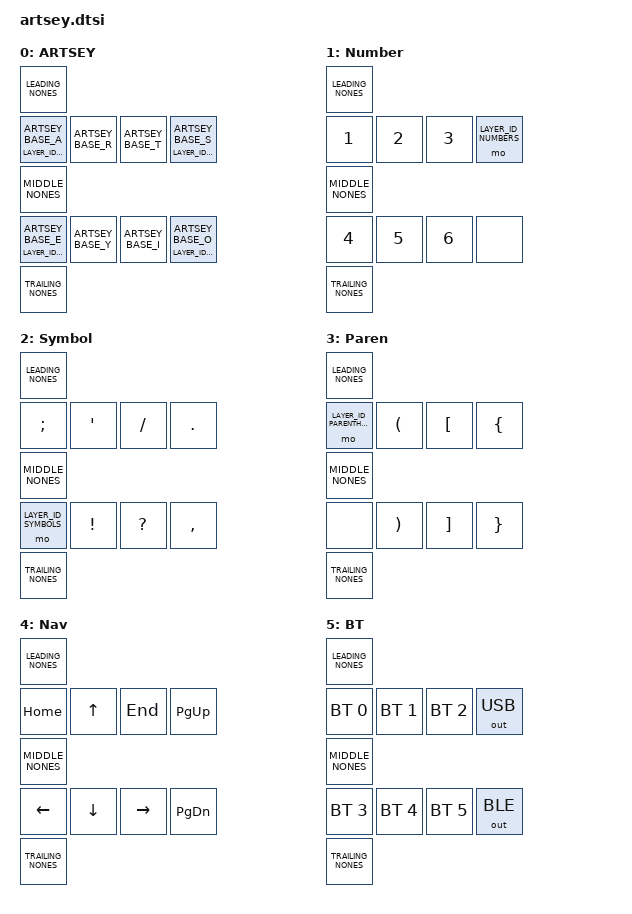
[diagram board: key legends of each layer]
/*
 * Copyright (c) 2021 Mike "KemoNine" Crosson
 *
 * SPDX-License-Identifier: MIT
 */

#include <behaviors.dtsi>
#include <dt-bindings/zmk/keys.h>
#include <dt-bindings/zmk/outputs.h>

#define ZMK_POINTING_DEFAULT_MOVE_VAL 500  // default: 600
#define ZMK_POINTING_DEFAULT_SCRL_VAL 15    // default: 10

#include <dt-bindings/zmk/pointing.h>

&mmv {
    x-input-code = <INPUT_REL_X>;
    y-input-code = <INPUT_REL_Y>;
    time-to-max-speed-ms = <0>;
    acceleration-exponent = <0>;
};

&msc {
    x-input-code = <INPUT_REL_HWHEEL>;
    y-input-code = <INPUT_REL_WHEEL>;
    time-to-max-speed-ms = <0>;
    acceleration-exponent = <0>;
};

/*****************************************
 * Macros for filling in "&none" in the right places in the keymap for re-use needs
 *****************************************/
#define NONE0(X)
#define NONE1(X) X
#define NONE2(X) NONE1(X) X
#define NONE3(X) NONE2(X) X
#define NONE4(X) NONE3(X) X
#define NONE5(X) NONE4(X) X
#define NONE6(X) NONE5(X) X
#define NONE7(X) NONE6(X) X
#define NONE8(X) NONE7(X) X
#define NONE9(X) NONE8(X) X
#define NONE10(X) NONE9(X) X

#define NONE(HUNDREDS,TENS,ONES) \
  NONE##HUNDREDS(NONE10(NONE10(&none))) \
  NONE##TENS(NONE10(&none)) \
  NONE##ONES(&none)

/*****************************************
 * ARTSEY website : https://www.artsey.io
 * Primary reference : https://www.artsey.io/_FILES/images/ARTSEY.jpg
*****************************************/

/*****************************************
 * Setting up ARTSEY comboing
 *   - Enabled right OR left handed orientation
 *   - Please note: A/E key positions should be on your INDEX finger
 *     - The online reference is for right handed use
 *     - When using the ARTSEY layout left handed you'll want to ensure your keypositions are flipped along the Y axis
 *   - Update/adjust the key positions using your boards keymap 
 *     - See below for additional details
 *   - YOU MUST SET THE FOLLOWING CONFIG VALUES FOR THIS SETUP TO WORK PROPERLY IN YOUR BOARDS .conf FILE
 *     - CONFIG_ZMK_COMBO_MAX_COMBOS_PER_KEY=16
 *     - CONFIG_ZMK_COMBO_MAX_KEYS_PER_COMBO=8
 *     - CONFIG_ZMK_COMBO_MAX_PRESSED_COMBOS=8
 *****************************************/

/*****************************************
 * Define which layout you want to use
 *  ONLY ENABLE ONE OF THESE
*****************************************/
#define ARTSEY_RIGHT 1


/*****************************************
 * Define key positions used for combos
 * These definitions are used to define the various ARTSEY combos
 * 
 * Please see the documentation on "combos" for details on how to find the proper key positions
 *
 * Default key positions are for a generic 4x2 keyboard and should NOT be used outright
 * DEFINE these definitions in your boards keymap BEFORE including artsey.dtsi
*****************************************/
// ARTS Row
// #define KEY_A 0
// #define KEY_R 1
// #define KEY_T 2
// #define KEY_S 3
// EYIO Row
// #define KEY_E 4
// #define KEY_Y 5
// #define KEY_I 6
// #define KEY_O 7
// Big artsey F1-12 layer keys for combo
// #define KEY_F_TOP -1
// #define KEY_F_BOTTOM -1

/*****************************************
 * Define key position offsets in main keymap
 *
 * In order to make this keymap flexible, you must setup the number of &none "offsets" to use
 * The defines below should be set in your LOCAL keymap and using the above "NONE([hundreds],[tens],[ones])" macro for filling in the gaps
*****************************************/
// #define LEADING_NONES NONE(0, 1, 0)
// #define MIDDLE_NONES NONE(0, 0, 3)
// #define TRAILING_NONES NONE(0, 1, 0)
// #define BIG_LEADING_NONES NONE(0, 0, 0)
// #define BIG_BETWEEN_ROW_ONE_TWO_NONES NONE(0, 0, 0)
// #define BIG_BETWEEN_ROW_TWO_THREE_NONES NONE(0, 0, 0)
// #define BIG_BETWEEN_ROW_THREE_THUMBS NONE(0, 0, 0)
// #define BIG_TRAILING_NONES NONE(0, 0, 0)

/*****************************************
 * Define custom BT layer extra keys
 *
 * You can override the 2 blank keys on the BT select layer by copy/pasting the below into your keymap
 *     *before* including the artsey.dtsfile
 * Once added to your keymap you can adjust these 2 keys as you see fit
*****************************************/
#if !defined ARTSEY_BT_TOP
#define ARTSEY_BT_TOP &out OUT_BLE
#endif
#if !defined ARTSEY_BT_BOTTOM
#define ARTSEY_BT_BOTTOM &out OUT_USB
#endif

/*****************************************
 * Define how long it takes for the combos/holds to 'time out'
 * See documentation on "combos" for more detail
 * THE COMBO TIMEOUTS MUST BE THE SAME
 *    https://github.com/zmkfirmware/zmk/issues/905
 *****************************************/
#if !defined TIMEOUT_COMBO_2
#define TIMEOUT_COMBO_2 175
#endif
#if !defined TIMEOUT_COMBO_3
#define TIMEOUT_COMBO_3 175
#endif
#if !defined TIMEOUT_COMBO_MOUSE
#define TIMEOUT_COMBO_MOUSE 175
#endif
#if !defined TIMEOUT_COMBO_4
#define TIMEOUT_COMBO_4 175
#endif
#if !defined TIMEOUT_COMBO_8
#define TIMEOUT_COMBO_8 175
#endif
#if !defined TIMEOUT_LAYER_HOLD
#define TIMEOUT_LAYER_HOLD 200
#endif
#if !defined TIMEOUT_STICKY_LEADER_KEY
#define TIMEOUT_STICKY_LEADER_KEY 5000
#endif
&sk {
	release-after-ms = <TIMEOUT_STICKY_LEADER_KEY>;
};
&sl { 
	release-after-ms = <TIMEOUT_STICKY_LEADER_KEY>;
};

/*****************************************
 * Define custom layer
 *
 * You can override this layer by copy/pasting the into your keymap *before* including the artsey.dtsi file
 * Once added to your keymap you can adjust as you see fit
*****************************************/
#if !defined ARTSEY_LAYER_CUSTOM
#if defined ARTSEY_RIGHT
#define ARTSEY_LAYER_CUSTOM                                            \
		custom {                                                       \
			label = "Custom";                                          \
			bindings = <                                               \
				LEADING_NONES                                          \
				&kp C_BRI_UP &kp C_MUTE   &kp C_VOL_UP  &none               \
				MIDDLE_NONES                                           \
				&sk C_BRI_DN  &kp C_PLAY_PAUSE &kp C_VOL_DN  &mo LAYER_ID_CUSTOM \
				TRAILING_NONES                                         \
			>;                                                         \
		};
#endif

#endif

#if !defined ARTSEY_LAYER_MOUSE
#if defined ARTSEY_RIGHT
#define ARTSEY_LAYER_MOUSE                                            \
		mouse {   								\
			label = "Mouse";                            			                \
			bindings = <                                               \
				LEADING_NONES                                          \
				&mkp LCLK &mmv MOVE_UP  &mkp RCLK  &msc SCRL_UP              \
				MIDDLE_NONES                                           \
				&mmv MOVE_LEFT &mmv MOVE_DOWN  &mmv MOVE_RIGHT &msc SCRL_DOWN \
				TRAILING_NONES                                         \
			>;                                                         \
		};
#endif

#endif

/*****************************************
 * Define base layer chars for 'standard ARTSEY' or 'COLEMAK' inspired (you can add more by following the pattern below)
 * Turn on the ARTSEY_COLEMAK definition above if you want this change
 *****************************************/
#define ARTSEY_BASE_A A
#define ARTSEY_BASE_R R
#define ARTSEY_BASE_T T
#define ARTSEY_BASE_S S
#define ARTSEY_BASE_E E
#define ARTSEY_BASE_Y Y
#define ARTSEY_BASE_I I
#define ARTSEY_BASE_O O
#define ARTSEY_COMBO_N N

/*****************************************
 * Layer IDs used by the ARTSEY keymap
 * Do NOT change these and do NOT change the order of the layers as shown below
 *****************************************/
#define LAYER_ID_GLOBAL -1
#define LAYER_ID_BASE 0
#define LAYER_ID_NUMBERS 1
#define LAYER_ID_SYMBOLS 2
#define LAYER_ID_PARENTHETICALS 3
#define LAYER_ID_NAVIGATION 4
#define LAYER_ID_MOUSE 5
#define LAYER_ID_BT_SEL 6
#define LAYER_ID_CUSTOM 7


/*****************************************
 * Standard ARTSEY combo definitions
 * These should NOT be changed and are global in scope
 *****************************************/
/ {
	combos {
		compatible = "zmk,combos";
		/*****************************************
		 * 2 key combos
		 *****************************************/
		
		combo_enter      { layers = <LAYER_ID_BASE>; timeout-ms = <TIMEOUT_COMBO_2>; key-positions = <KEY_A KEY_E>; bindings = <&kp ENTER>; };
		combo_control    { layers = <LAYER_ID_BASE>; timeout-ms = <TIMEOUT_COMBO_2>; key-positions = <KEY_E KEY_S>; bindings = <&sk LCTRL>; };
		combo_gui        { layers = <LAYER_ID_BASE>; timeout-ms = <TIMEOUT_COMBO_2>; key-positions = <KEY_Y KEY_S>; bindings = <&sk LGUI>; };
		combo_alt        { layers = <LAYER_ID_BASE>; timeout-ms = <TIMEOUT_COMBO_2>; key-positions = <KEY_I KEY_S>; bindings = <&sk LALT>; };
		combo_backspace  { layers = <LAYER_ID_BASE>; timeout-ms = <TIMEOUT_COMBO_2>; key-positions = <KEY_E KEY_R>; bindings = <&kp BACKSPACE>; };
		combo_delete     { layers = <LAYER_ID_BASE>; timeout-ms = <TIMEOUT_COMBO_2>; key-positions = <KEY_I KEY_R>; bindings = <&kp DELETE>; };
		// combo_shift_lock { layers = <LAYER_ID_BASE>; timeout-ms = <TIMEOUT_COMBO_2>; key-positions = <KEY_R KEY_Y>; bindings = <&kt LSHFT>; };
		// combo_mmb      { layers = <LAYER_ID_MOUSE>; timeout-ms = <TIMEOUT_COMBO_MOUSE>; key-positions = <KEY_S KEY_O>; bindings = <&mkp MB3>; };

		combo_space2      { layers = <LAYER_ID_BASE>; timeout-ms = <TIMEOUT_COMBO_2>; key-positions = <KEY_E KEY_O>; bindings = <&kp SPACE>; };
		combo_c           { layers = <LAYER_ID_BASE>; timeout-ms = <TIMEOUT_COMBO_2>; key-positions = <KEY_E KEY_Y>; bindings = <&kp C>; };
		combo_n           { layers = <LAYER_ID_BASE>; timeout-ms = <TIMEOUT_COMBO_2>; key-positions = <KEY_I KEY_O>; bindings = <&kp ARTSEY_COMBO_N>; };
		combo_f           { layers = <LAYER_ID_BASE>; timeout-ms = <TIMEOUT_COMBO_2>; key-positions = <KEY_A KEY_R>; bindings = <&kp F>; };
		combo_b           { layers = <LAYER_ID_BASE>; timeout-ms = <TIMEOUT_COMBO_2>; key-positions = <KEY_A KEY_T>; bindings = <&kp B>; };
		combo_g           { layers = <LAYER_ID_BASE>; timeout-ms = <TIMEOUT_COMBO_2>; key-positions = <KEY_R KEY_T>; bindings = <&kp G>; };
		combo_u           { layers = <LAYER_ID_BASE>; timeout-ms = <TIMEOUT_COMBO_2>; key-positions = <KEY_Y KEY_I>; bindings = <&kp U>; };
		combo_h           { layers = <LAYER_ID_BASE>; timeout-ms = <TIMEOUT_COMBO_2>; key-positions = <KEY_E KEY_I>; bindings = <&kp H>; };
		combo_v           { layers = <LAYER_ID_BASE>; timeout-ms = <TIMEOUT_COMBO_2>; key-positions = <KEY_R KEY_S>; bindings = <&kp V>; };
		combo_j           { layers = <LAYER_ID_BASE>; timeout-ms = <TIMEOUT_COMBO_2>; key-positions = <KEY_T KEY_S>; bindings = <&kp J>; };
		combo_w           { layers = <LAYER_ID_BASE>; timeout-ms = <TIMEOUT_COMBO_2>; key-positions = <KEY_A KEY_S>; bindings = <&kp W>; };
		combo_k           { layers = <LAYER_ID_BASE>; timeout-ms = <TIMEOUT_COMBO_2>; key-positions = <KEY_Y KEY_O>; bindings = <&kp K>; };
		combo_comma       { layers = <LAYER_ID_BASE>; timeout-ms = <TIMEOUT_COMBO_2>; key-positions = <KEY_A KEY_Y>; bindings = <&none>; };
		combo_period      { layers = <LAYER_ID_BASE>; timeout-ms = <TIMEOUT_COMBO_2>; key-positions = <KEY_A KEY_I>; bindings = <&none>; };
		combo_slash       { layers = <LAYER_ID_BASE>; timeout-ms = <TIMEOUT_COMBO_2>; key-positions = <KEY_A KEY_O>; bindings = <&none>; };
		combo_exclamation { layers = <LAYER_ID_BASE>; timeout-ms = <TIMEOUT_COMBO_2>; key-positions = <KEY_T KEY_I>; bindings = <&none>; };
		combo_question    { layers = <LAYER_ID_BASE>; timeout-ms = <TIMEOUT_COMBO_2>; key-positions = <KEY_R KEY_Y>; bindings = <&none>; };
		
		combo_seven { layers = <LAYER_ID_NUMBERS>; timeout-ms = <TIMEOUT_COMBO_2>; key-positions = <KEY_A KEY_R>; bindings = <&kp N7>; };
		combo_eight { layers = <LAYER_ID_NUMBERS>; timeout-ms = <TIMEOUT_COMBO_2>; key-positions = <KEY_R KEY_T>; bindings = <&kp N8>; };
		combo_nine  { layers = <LAYER_ID_NUMBERS>; timeout-ms = <TIMEOUT_COMBO_2>; key-positions = <KEY_E KEY_Y>; bindings = <&kp N9>; };
		combo_zero  { layers = <LAYER_ID_NUMBERS>; timeout-ms = <TIMEOUT_COMBO_2>; key-positions = <KEY_Y KEY_I>; bindings = <&kp N0>; };

		/*****************************************
		 * 3 key combos
		 *****************************************/
		combo_esc              { layers = <LAYER_ID_BASE>; timeout-ms = <TIMEOUT_COMBO_3>; key-positions = <KEY_A KEY_R KEY_O>; bindings = <&kp ESC>; };
		combo_layer_navigation { layers = <LAYER_ID_BASE LAYER_ID_NAVIGATION>; timeout-ms = <TIMEOUT_COMBO_3>; key-positions = <KEY_R KEY_E KEY_I>; bindings = <&tog LAYER_ID_NAVIGATION>; };
		combo_layer_mouse { layers = <LAYER_ID_BASE>; timeout-ms = <TIMEOUT_COMBO_3>; key-positions = < KEY_Y>; bindings = <&tog LAYER_ID_MOUSE>; };
		combo_layer_mouse_exit { layers = <LAYER_ID_MOUSE>; timeout-ms = <TIMEOUT_COMBO_MOUSE>; key-positions = <KEY_S KEY_O>; bindings = <&tog LAYER_ID_MOUSE>; };

		combo_m            { layers = <LAYER_ID_BASE>; timeout-ms = <TIMEOUT_COMBO_3>; key-positions = <KEY_Y KEY_I KEY_O>; bindings = <&kp M>; };
		combo_d            { layers = <LAYER_ID_BASE>; timeout-ms = <TIMEOUT_COMBO_3>; key-positions = <KEY_A KEY_R KEY_T>; bindings = <&kp D>; };
		combo_p            { layers = <LAYER_ID_BASE>; timeout-ms = <TIMEOUT_COMBO_3>; key-positions = <KEY_E KEY_I KEY_O>; bindings = <&kp P>; };
		combo_q            { layers = <LAYER_ID_BASE>; timeout-ms = <TIMEOUT_COMBO_3>; key-positions = <KEY_A KEY_T KEY_S>; bindings = <&kp Q>; };
		combo_x            { layers = <LAYER_ID_BASE>; timeout-ms = <TIMEOUT_COMBO_3>; key-positions = <KEY_R KEY_T KEY_S>; bindings = <&kp X>; };
		combo_l            { layers = <LAYER_ID_BASE>; timeout-ms = <TIMEOUT_COMBO_3>; key-positions = <KEY_E KEY_Y KEY_I>; bindings = <&kp L>; };
		combo_single_quote { layers = <LAYER_ID_BASE>; timeout-ms = <TIMEOUT_COMBO_3>; key-positions = <KEY_A KEY_Y KEY_I>; bindings = <&none>; };
		
		/*****************************************
		 * 4 key combos
		 *****************************************/
		combo_tab             { layers = <LAYER_ID_BASE>; timeout-ms = <TIMEOUT_COMBO_4>; key-positions = <KEY_A KEY_R KEY_T KEY_O>; bindings = <&kp TAB>; };
		combo_space           { layers = <LAYER_ID_BASE>; timeout-ms = <TIMEOUT_COMBO_4>; key-positions = <KEY_E KEY_Y KEY_I KEY_O>; bindings = <&kp SPACE>; };
		combo_shift           { layers = <LAYER_ID_BASE>; timeout-ms = <TIMEOUT_COMBO_4>; key-positions = <KEY_E KEY_R KEY_T KEY_S>; bindings = <&sk LSHFT>; };
		combo_layer_bt_select { layers = <LAYER_ID_BASE LAYER_ID_BT_SEL>; timeout-ms = <TIMEOUT_COMBO_4>; key-positions = <KEY_A KEY_E KEY_S KEY_O>; bindings = <&tog LAYER_ID_BT_SEL>; };
		combo_bt_clr          { layers = <LAYER_ID_BT_SEL>; timeout-ms = <TIMEOUT_COMBO_4>; key-positions = <KEY_R KEY_Y KEY_T KEY_I>; bindings = <&bt BT_CLR_ALL>; };

		combo_z         { layers = <LAYER_ID_BASE>; timeout-ms = <TIMEOUT_COMBO_4>; key-positions = <KEY_A KEY_R KEY_T KEY_S>; bindings = <&kp Z>; };
		combo_caps_lock { layers = <LAYER_ID_BASE>; timeout-ms = <TIMEOUT_COMBO_4>; key-positions = <KEY_O KEY_I KEY_Y KEY_A>; bindings = <&kp CAPS>; };

		/*****************************************
		 * 8 key reset
		 *****************************************/
		combo_reset          { layers = <LAYER_ID_BT_SEL LAYER_ID_MOUSE LAYER_ID_NAVIGATION>; timeout-ms = <TIMEOUT_COMBO_8>; key-positions = <KEY_A KEY_R KEY_T KEY_S KEY_E KEY_Y KEY_I KEY_O>; bindings = <&to LAYER_ID_BASE>; };
	};
};

/*****************************************
 * Standard ARTSEY layer activation definitions
 * These should NOT be changed and are global in scope
 *****************************************/
/ {
	behaviors {
		layer_base_kp: layer_base_kp { compatible = "zmk,behavior-hold-tap"; label = "layer_base_kp"; 
						#binding-cells = <2>; tapping_term_ms = <TIMEOUT_LAYER_HOLD>; flavor = "tap-preferred"; 
						bindings = <&mo>, <&kp>; };
		layer_numbers_kp: layer_numbers_kp { compatible = "zmk,behavior-hold-tap"; label = "layer_numbers_kp"; 
						#binding-cells = <2>; tapping_term_ms = <TIMEOUT_LAYER_HOLD>; flavor = "tap-preferred"; 
						bindings = <&mo>, <&kp>; };
		layer_symbols_kp: layer_symbols_kp { compatible = "zmk,behavior-hold-tap"; label = "layer_symbols_kp"; 
						#binding-cells = <2>; tapping_term_ms = <TIMEOUT_LAYER_HOLD>; flavor = "tap-preferred"; 
						bindings = <&mo>, <&kp>; };
		layer_parentheticals_kp: layer_parentheticals_kp { compatible = "zmk,behavior-hold-tap"; label = "layer_parentheticals_kp";
						#binding-cells = <2>; tapping_term_ms = <TIMEOUT_LAYER_HOLD>; flavor = "tap-preferred";
						bindings = <&mo>, <&kp>; };
		layer_custom_kp: layer_custom_kp { compatible = "zmk,behavior-hold-tap"; label = "layer_custom_kp";
						#binding-cells = <2>; tapping_term_ms = <TIMEOUT_LAYER_HOLD>; flavor = "tap-preferred";
						bindings = <&mo>, <&kp>; };
		ctrl_alt_kp: ctrl_alt_kp { compatible = "zmk,behavior-hold-tap"; label = "ctrl_alt_kp";
						#binding-cells = <2>; tapping_term_ms = <TIMEOUT_LAYER_HOLD>; flavor = "tap-preferred";
						bindings = <&sk>, <&sk>; };
	};
};

/*****************************************
 * Standard ARTSEY layer definitions 
 * !!!!!!!!!! FOR RIGHT HANDED USE !!!!!!!!!!
 *****************************************/
#if defined ARTSEY_RIGHT
/ {
	keymap {
		compatible = "zmk,keymap";
		base {
			label = "ARTSEY";
			bindings = <
				LEADING_NONES
				&layer_parentheticals_kp LAYER_ID_PARENTHETICALS ARTSEY_BASE_A  &kp ARTSEY_BASE_R     &kp ARTSEY_BASE_T     &layer_numbers_kp LAYER_ID_NUMBERS ARTSEY_BASE_S
				MIDDLE_NONES
				&layer_symbols_kp LAYER_ID_SYMBOLS ARTSEY_BASE_E                &kp ARTSEY_BASE_Y     &kp ARTSEY_BASE_I     &layer_custom_kp LAYER_ID_CUSTOM ARTSEY_BASE_O
				TRAILING_NONES
			>;
		};
		numbers {
			label = "Number";
			bindings = <
				LEADING_NONES
				&kp N1                                              &kp N2    &kp N3    &mo LAYER_ID_NUMBERS
				MIDDLE_NONES
				&kp N4                                              &kp N5    &kp N6    &none
				TRAILING_NONES
			>;
		};
		symbols {
			label = "Symbol";
			bindings = <
				LEADING_NONES
				&kp SEMI                                            &kp SQT  &kp SLASH  &kp PERIOD
				MIDDLE_NONES
				&mo LAYER_ID_SYMBOLS                                &kp EXCL &kp QMARK &kp COMMA
				TRAILING_NONES
			>;
		};
		parentheticals {
			label = "Paren";
			bindings = <
				LEADING_NONES
				&mo LAYER_ID_PARENTHETICALS                         &kp LPAR  &kp LBKT  &kp LBRC
				MIDDLE_NONES
				&none                                               &kp RPAR  &kp RBKT  &kp RBRC
				TRAILING_NONES
			>;
		};
		navigation {
			label = "Nav";
			bindings = <
				LEADING_NONES
				&kp HOME                                            &kp UP    &kp END   &kp PG_UP
				MIDDLE_NONES
				&kp LEFT                                            &kp DOWN  &kp RIGHT &kp PG_DN
				TRAILING_NONES
			>;
		};
		ARTSEY_LAYER_MOUSE
		bt {
			label = "BT";
			bindings = <
				LEADING_NONES
				&bt BT_SEL 0 &bt BT_SEL 1 &bt BT_SEL 2 &out OUT_USB
				MIDDLE_NONES
				&bt BT_SEL 3 &bt BT_SEL 4 &bt BT_SEL 5 &out OUT_BLE
				TRAILING_NONES
			>;
		};
		ARTSEY_LAYER_CUSTOM 
	};
};
#endif

